# dm64lc_cslr_pci_002 register map
Vendor: Texas Instruments
Peripheral module from a debugger description file.
Registers are 32-bit, access not given, reset 0x0 unless marked. A register's access mark holds for its fields unless they carry their own. Offsets are as the file gives them; lines under a group give offsets from that group; [hi:lo] are bit positions; {n}, {i} and the like mark numbered series; 'fields as' and 'values as' point back to an identical list; <NAME> marks a mode.

## PCICFG — Peripheral Component Interconnect Interface
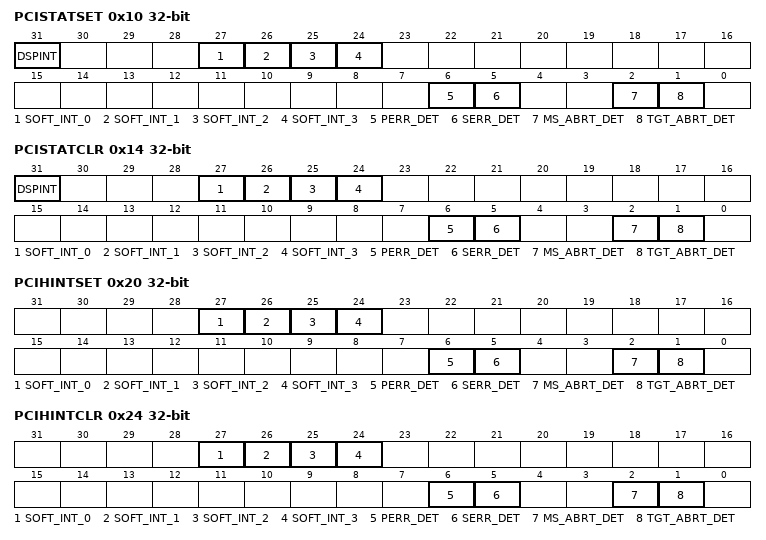
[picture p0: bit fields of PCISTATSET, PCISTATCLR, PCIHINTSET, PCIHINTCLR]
0x10 PCISTATSET — Sets internal Status Register
  [31] DSPINT — DSP interrupt bit. Writing a 1 to this bit forces a host-to-DSP interrupt (DSPINT). The DSPINT bit of the internal Back End Application Interrupt Enable Register must be set to 1 before the interrupt can reach the DSP. 0 A write of 0 is ignored. 1 Host-to-DSP interrupt (DSPINT) is asserted. (access RW1S)
  [27-n] SOFT_INT_{n} (n=0..3) — Software interrupt set bits. Writing a 1 to these bits sets the corresponding software interrupt. If the corresponding bit in the PCI Host Interrupt Enable Register is also set to 1, an interrupt is generated to the host via the PINTA pin. The host-to-DSP interrupt (DSPINT) is also generated if the corresponding bit in the PCI Back End Application Interrupt Enable Register is set to 1. 0 A write of 0 is ignored 1 Generate software interrupt (access RW1S)
  [6] PERR_DET — Parity error detect bit. Writing a 1 to this bit set a parity error. 0 A write of 0 is ignored. 1 Set parity error (access RW1S)
  [5] SERR_DET — System error detect bit. Writing a 1 to this bit set a system error. 0 A write of 0 is ignored. 1 Set system error (access RW1S)
  [2] MS_ABRT_DET — Master abort detect bit. Writing a 1 to this bit set master abort. 0 A write of 0 is ignored. 1 Set master abort (access RW1S)
  [1] TGT_ABRT_DET — Set target abort detect bit.Writing a 1 to this bit set target abort. 0 A write of 0 is ignored. 1 Set target abort (access RW1S)
0x14 PCISTATCLR — Clears internal Status Register
  [31] DSPINT — DSP interrupt bit. Writing a 1 to this bit deasserts the host-to-DSP interrupt (DSPINT). 0 A write of 0 is ignored. 1 Host-to-DSP interrupt (DSPINT) is deasserted. (access RW1C)
  [27-n] SOFT_INT_{n} (n=0..3) — Software interrupt clear bits. Writing a 1 to these bits clears the corresponding software interrupt. 0 A write of 0 is ignored 1 Clear software interrupt (access RW1C)
  [6] PERR_DET — Parity Error Detect bit. Writing 1 to this bit Clear the parity error bit. 0 A write of 0 is ignored. 1 Clear the parity error (access RW1C)
  [5] SERR_DET — Sytem Error Detect bit. Writing 1 to this bit clear system error bit. 0 A write of 0 is ignored. 1 Clear the system error (access RW1C)
  [2] MS_ABRT_DET — Master abort detect bit. Writing 1 to this bit clear master abort error bit. 0 A write of 0 is ignored. 1 Clears master abort (access RW1C)
  [1] TGT_ABRT_DET — Target abort detect bit. Writing 1 to this bit clear target abort error bit. 0 A write of 0 is ignored. 1 Clears target abort (access RW1C)
0x20 PCIHINTSET — Set internal Host Interrupt Enable Register
  [27-n] SOFT_INT_{n} (n=0..3) — Software interrupt enable bits. Writing a 1 to these bits enables the corresponding software interrupt. When the corresponding bit in the internal Status Register is set to 1, an interrupt is generated to the host via the PINTA pin. 0 A write of 0 is ignored 1 Enables software interrupt (access RW1S)
  [6] PERR_DET — Parity error detect enable bit. Writing 1 to this bit allows an interrupt to be generated to the host when a parity error is detected. 0 A write of 0 is ignored. 1 Enables interrupt to host when parity error is detected (access RW1S)
  [5] SERR_DET — System error detect enable bit. Writing 1 to this bit allows an interrupt to be generated to the host when a system error is detected 0 A write of 0 is ignored. 1 Enables interrupt to host when system error is detected (access RW1S)
  [2] MS_ABRT_DET — Master abort detect enable bit. Writing 1 to this bit allows an interrupt to be generated to the host when a master abort is detected. 0 A write of 0 is ignored. 1 Enables interrupt to the host when master abort is detected (access RW1S)
  [1] TGT_ABRT_DET — Target abort detect enable bit. Writing 1 to this bit allows an interrupt to be generated to the host when a target abort is detected 0 A write of 0 is ignored. 1 Enables interrupt to the host when a target abort is detected (access RW1S)
0x24 PCIHINTCLR — Clear internal Host Interrupt Enable Register
  [27-n] SOFT_INT_{n} (n=0..3) — Software interrupt disable bits. Writing a 1 to these bits disables the corresponding software interrupt. 0 A write of 0 is ignored 1 Disables software interrupt (access RW1C)
  [6] PERR_DET — Parity error detect disable bit. Writing 1 to this bit disable the parity error detection 0 A write of 0 is ignored. 1 Disables the parity error detection (access RW1C)
  [5] SERR_DET — System error detect disable bit. Writing 1 to this bit disable the system error detection 0 A write of 0 is ignored. 1 Disables the System error detection (access RW1C)
  [2] MS_ABRT_DET — Master abort detect disable bit. Writing 1 to this bit disable the master abort detection 0 A write of 0 is ignored. 1 Disables the master abort detection (access RW1C)
  [1] TGT_ABRT_DET — Master abort detect disable bit. Writing 1 to this bit disable the master abort detection 0 A write of 0 is ignored. 1 Disables the master abort detection (access RW1C)
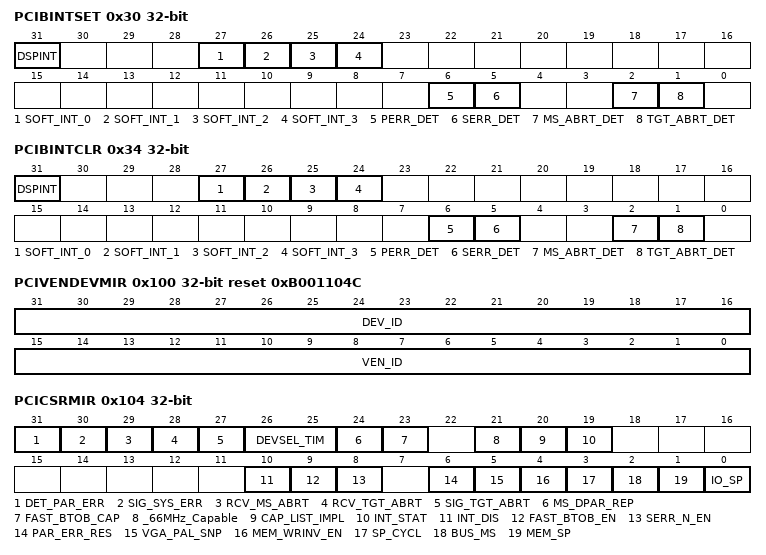
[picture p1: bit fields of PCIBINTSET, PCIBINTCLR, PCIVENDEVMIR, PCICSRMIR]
0x30 PCIBINTSET — Set internal Back End Application Interrupt Enable Register
  [31] DSPINT — DSP interrupt enable bit. Writing a 1 to this bit enables the host-to-DSP interrupt (DSPINT). 0 A write of 0 is ignored. 1 Enables the host-to-DSP interrupt (DSPINT). (access RW1S)
  [27-n] SOFT_INT_{n} (n=0..3) — Software interrupt enable bits. Writing a 1 to these bits enables the corresponding software interrupt. When the corresponding bit in the internal Status Register is set to 1, an interrupt is generated to the DSP via the DSPINT interrupt line. 0 A write of 0 is ignored 1 Enables software interrupt (access RW1S)
  [6] PERR_DET — Parity error detect enable bit. Writing a 1 to this bit enables the Parity error detection 0 A write of 0 is ignored. 1 Enables the parity error detection (access RW1S)
  [5] SERR_DET — System error detect enable bit. Writing a 1 to this bit enables the System error detection 0 A write of 0 is ignored. 1 Enables the system error detection (access RW1S)
  [2] MS_ABRT_DET — Master abort detect enable bit. Writing a 1 to this bit enables the Maste abort detection error 0 A write of 0 is ignored. 1 Enables the master abort detection (access RW1S)
  [1] TGT_ABRT_DET — Target abort detect enable bit. Writing a 1 to this bit enables the Target abort detection error 0 A write of 0 is ignored. 1 Enables the target abort detection (access RW1S)
0x34 PCIBINTCLR — Clear internal Back End Application Interrupt Enable Register
  [31] DSPINT — DSP interrupt disable bit. Writing a 1 to this bit disables the host-to-DSP interrupt (DSPINT). 0 A write of 0 is ignored. 1 Disables the host-to-DSP interrupt (DSPINT). (access RW1C)
  [27-n] SOFT_INT_{n} (n=0..3) — Software interrupt disable bits. Writing a 1 to these bits disables the corresponding software interrupt. 0 A write of 0 is ignored 1 Disables software interrupt (access RW1C)
  [6] PERR_DET — Parity error detect disable bit. Writing a 1 to this bit disable the Parity error detection 0 A write of 0 is ignored. 1 Disables the parity error detection (access RW1C)
  [5] SERR_DET — System error detect disable bit. Writing a 1 to this bit disable the System error detection 0 A write of 0 is ignored. 1 Disables the system error detection (access RW1C)
  [2] MS_ABRT_DET — Master abort detect disable bit. Writing a 1 to this bit disable the Master abort detection 0 A write of 0 is ignored. 1 Disables the master abort detection (access RW1C)
  [1] TGT_ABRT_DET — Target abort detect disable bit.Writing a 1 to this bit disable the Target abort detection 0 A write of 0 is ignored. 1 Disables the target abort detection (access RW1C)
0x100 PCIVENDEVMIR rw reset 0xB001104C — This register is used to initialize the Vendor ID and / or Device ID in the PCI Configuration Space
  [31:16] DEV_ID — Device ID. Identifies a specific device from the manufacturer. The Device ID is specified by the device manufacturer
  [15:0] VEN_ID — Vendor ID.Uniquely identifies the manufacturer of the device. The Vendor ID is specified by the PCI Special Interest Group to insure uniqueness
0x104 PCICSRMIR (reset mask 0xF9FFFFFF) — This register is used to initialize certain bits in the PCI Configuration Space Command / Status register
  [31] DET_PAR_ERR — Detected Parity Error bit. This bit is set by the PCI to indicate that it detected a parity error (access RW1C)
  [30] SIG_SYS_ERR — Signaled System Error bit.This bit is set by the PCI to indicate that it signaled a system error on the PSERR pin. (access RW1C)
  [29] RCV_MS_ABRT — Received Master Abort bit.This bit is set by the PCI master unit in the PCI to indicate that it terminated a transaction with a master abort (access RW1C)
  [28] RCV_TGT_ABRT — Received Target Abort bit.This bit is set by the PCI master unit in the PCI to indicate that it has received a target abort when acting as a bus master (access RW1C)
  [27] SIG_TGT_ABRT ro — Signaled Target Abort bit.This bit is always 0 since the PCI cannot issue a target abort
  [26:25] DEVSEL_TIM ro — DEVSEL timing bit.This bit indicates the decode response time capability of the device. This bit is hardwired to "01"
  [24] MS_DPAR_REP — Master Data Parity Reported bit This bit is set by the PCI master unit in the PCI when all of the following conditions are met. 1. The PCI asserted PPERR or observed PPERR asserted 2. The PCI master unit was the bus master during the observed PPERR assertion 3. The PAR_ERR_RES bit ( Bit 6) is Set. (access RW1C)
  [23] FAST_BTOB_CAP ro — Fast Back to Back Capable bit.This bit indicates that the device is capable of performing fast back to back transactions. This bit is hardwired to "0"
  [21] _66MHz_Capable rw — 66MHz Capable bit. This bit defaults to 0 since the PCI on DM643x devices only supports 33MHz operation.
  [20] CAP_LIST_IMPL rw — Capabilities List Implemented bit. This bit defaults to 0 since the PCI on DM643x devices does not implement a capabilities list
  [19] INT_STAT ro — Interrupt Status bit.This bit indicates the current interrupt status for the function as generated by the interrupt registers in the back end interface. If this bit is set and INT_DIS(bit 10) bit is cleared, the PINTA pin will be asserted low. The bit INT_DIS has no effect on the value of this bit.
  [10] INT_DIS rw — Interrupt Disable bit.This bit is a disable for the output driver on the PINTA pin. If this bit is set, the interrupt condition will not appear on the external PINTA pin
  [9] FAST_BTOB_EN ro — Fast Back to Back Enable bit.This bit controls whether or not the device is allowed to perform back to back writes to different targets. This bit is hardwired to a "0".
  [8] SERR_N_EN rw — System error enable bit is an enable for the output driver on the PSERR pin
  [6] PAR_ERR_RES rw — Parity Error response bit. This bit controls whether or not the device responds to detected parity errors. If this bit is set, the PCI will respond normally to parity errors. If this bit is cleared, the PCI will set its DET_PAR_ERR bit (Bit 31) when an error is detected, but does not assert PPERR and continues normal operation.
  [5] VGA_PAL_SNP ro — VGA Palette Snoop. This bit hardwired to a "0".
  [4] MEM_WRINV_EN rw — Memory Write and Invalidate Enable bit.This bit enables the device to use the Memory Write and Invalidate command.If this bit is cleared, the PCI will not attempt to use the Memory Write and Invalidate command.
  [3] SP_CYCL ro — Special Cycles bit controls the device's response to special cycle commands. If this bit is cleared, the device will ignore all special cycle commands. If this bit is set to 1, the device can monitor special cycle commands.
  [2] BUS_MS rw — Bus Master bit enables the device to act as a PCI bus master.If this bit is cleared, the device will not act as a master on the PCI bus.
  [1] MEM_SP rw — Memory Space bit enables the device to respond to memory accesses within it's address space.If this bit is cleared, the PCI will not respond to memory mapped accesses.
  [0] IO_SP ro — I/O Space bit enables the device to respond to I/O accesses within it's address space. If this bit is cleared, the PCI will not respond to IO mapped accesses.The PCI does not support IO accesses as a slave therefore this bit is hardwired to 0.
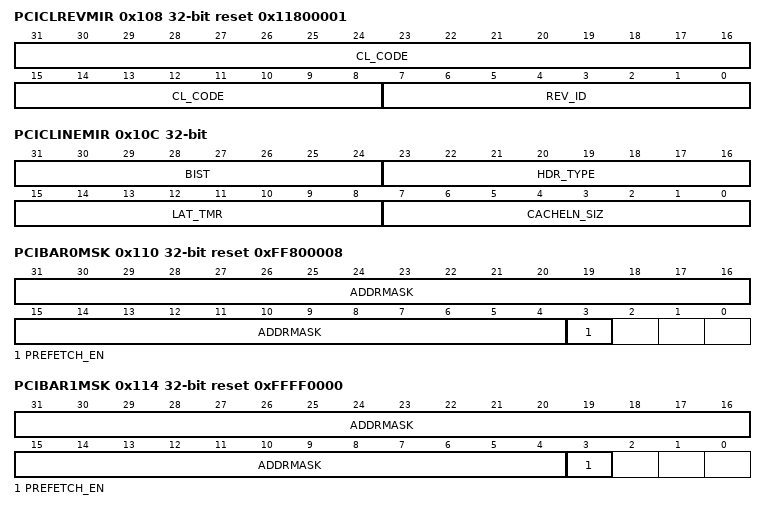
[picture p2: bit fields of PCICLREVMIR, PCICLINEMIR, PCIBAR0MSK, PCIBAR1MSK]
0x108 PCICLREVMIR rw reset 0x11800001 — This register is used to initialize the Class Code and / or Revision ID
  [31:8] CL_CODE — Class Code identifies the generic and specific function and programming interface of the device. The Class Code is specified by the device manufacturer
  [7:0] REV_ID — Revision ID identifies a revision of the specific device. The Revision ID is specified by the device manufacturer
0x10C PCICLINEMIR access per field — This register is used to set latency timer and cacheline size
  [31:24] BIST ro — Built-in Self Test bit. Hardwired to 0
  [23:16] HDR_TYPE ro — Header Type identifies the layout of bytes 10h through 3Fh and if the device is single or multi-function
  [15:8] LAT_TMR rw — Latency Timer is provided so that the host can restrict the continued usage of the PCI bus by a master involved in a multiple data cycle transaction.
  [7:0] CACHELN_SIZ rw — Cacheline Size is provided so that the host can inform the device of the cache line size in units of 32 bit words.The value of this register is used by the PCI as a master device to determine whether to use Memory Write, Memory Write and Invalidate, Read, Read Line, or Read Multiple commands for accessing memory. This register is also used by the slave state machine to determine the size of prefetches that are performed on the Slave Back End Interface. Supported values for this register are as follows: 0b00000000 - Disabled 0b00000100 -Cache Line is 16 bytes 0b00001000 - Cache Line is 32 bytes 0b00010000 - Cache Line is 64 bytes 0b00100000 - Cache Line is 128 bytes Writing an unsupported value to this register will result in the value being set to 0
0x110 PCIBAR0MSK reset 0xFF800008 — The Base Address Mask Registers control the size and prefetchability of the PCI Configuration Base Address Registers
  [31:4] ADDRMASK rw — Address Mask Bit.These bits control the writability of corresponding bits in the corresponding PCI Configuration Base Address Register.
  [3] PREFETCH_EN rw — Prefetchable enable. This bit specifies whether or not the memory space controlled by the corresponding PCI Configruation Base Address Register is prefetchable.This bit is reflected in bit 3 of the corresponding PCI Configuration Base Address Register
0x114 PCIBAR1MSK reset 0xFFFF0000 — The Base Address Mask Registers control the size and prefetchability of the PCI Configuration Base Address Registers
  [31:4] ADDRMASK rw — Address Mask Bit.These bits control the writability of corresponding bits in the corresponding PCI Configuration Base Address Register.
  [3] PREFETCH_EN rw — Prefetchable enable. This bit specifies whether or not the memory space controlled by the corresponding PCI Configruation Base Address Register is prefetchable. This bit is reflected in bit 3 of the corresponding PCI Configuration Base Address Register
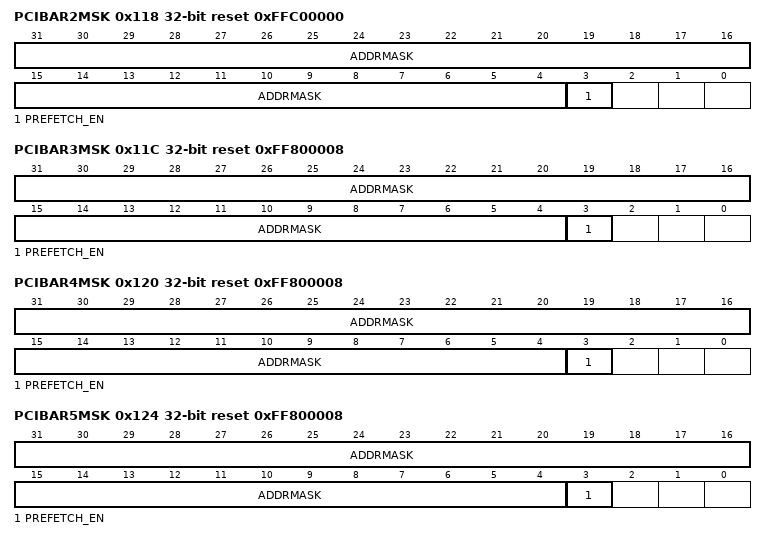
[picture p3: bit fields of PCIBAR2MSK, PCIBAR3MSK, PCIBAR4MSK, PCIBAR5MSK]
0x118 PCIBAR2MSK reset 0xFFC00000 — The Base Address Mask Registers control the size and prefetchability of the PCI Configuration Base Address Registers
  fields as PCIBAR1MSK
0x11C PCIBAR3MSK reset 0xFF800008 — The Base Address Mask Registers control the size and prefetchability of the PCI Configuration Base Address Registers
  fields as PCIBAR0MSK
0x120 PCIBAR4MSK reset 0xFF800008 — The Base Address Mask Registers control the size and prefetchability of the PCI Configuration Base Address Registers
  fields as PCIBAR1MSK
0x124 PCIBAR5MSK reset 0xFF800008 — The Base Address Mask Registers control the size and prefetchability of the PCI Configuration Base Address Registers
  fields as PCIBAR1MSK
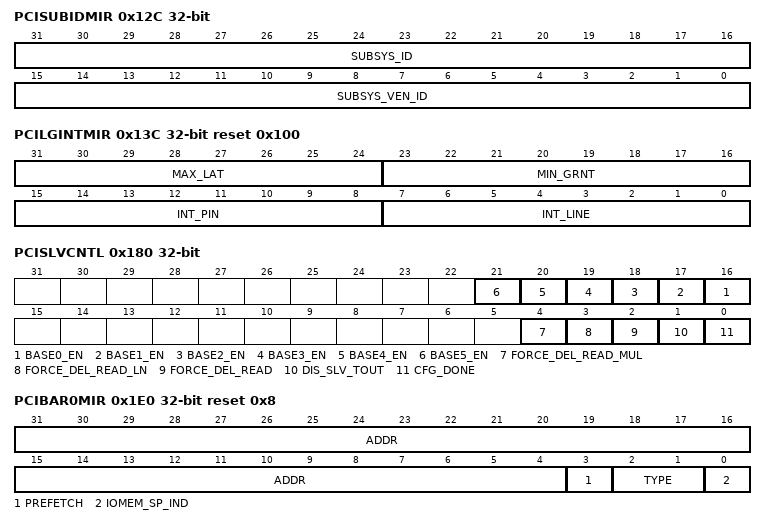
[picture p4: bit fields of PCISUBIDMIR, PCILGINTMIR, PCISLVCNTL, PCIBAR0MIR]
0x12C PCISUBIDMIR rw — PCI Subsystem Vendor ID / Subsystem ID
  [31:16] SUBSYS_ID — Subsystem Id. Identifies the board level device.The Subsystem ID is specified by the board level manufacturer.
  [15:0] SUBSYS_VEN_ID — Subsystem Vendor Id. Identifies the board level manufacturer. The Subsystem Vendor ID is specified by the PCI Special Interest Group.
0x134 PCICPBPTRMIR reset 0x40 — Capabilities Pointer
  [7:0] CAP ro — Capabilities Pointer. This constant specifies the address in configuration space where the first entry in the capabilities list is located.
0x13C PCILGINTMIR access per field reset 0x100 — Set Max Latency / Min Grant
  [31:24] MAX_LAT rw — Maximum Latency bit specifies how often the device needs to gain access to the PCI bus in 0.25 micro sec units.
  [23:16] MIN_GRNT rw — Minimum Grant bit specifies the length of the burst period for the device needs in 0.25 micro sec units.
  [15:8] INT_PIN ro — Interrupt Pin bit tells which interrupt pin the device uses. This register is hardwired to a 01h in the PCI to indicate that interrupt A will be used.
  [7:0] INT_LINE rw — Interrupt Line pin bit. The value in this 8 bit register is written by the host and indicates which input of the system interrupt controller the PCI interrupt pin is connected to.
0x180 PCISLVCNTL (reset mask 0xFFC0FFFF) — PCI Slave Control
  [n+16] BASE{n}_EN rw (n=0..5) — Enable/Disable BASE {n} Configuration 0 - Disable BASE {n} Configuration 1 - Enable BASE {n} Configuration
  [4] FORCE_DEL_READ_MUL rw — Force Delayed Read Multiple bit. 0 - Slave should respond with normal 16 clock cycle timeout and retry mechanism for Memory Read Multiple transactions 1 - Slave should immediately respond with a retry whenever a Memory Read Multiple transaction is decoded for this slave.
  [3] FORCE_DEL_READ_LN rw — Force Delayed Read Line bit. 0 - Slave should respond with normal 16 clock cycle timeout and retry mechanism for Memory Read Line transactions 1 - Slave should immediately respond with a retry whenever a Memory Read Line transaction is decoded for this slave.
  [2] FORCE_DEL_READ rw — Force Delayed Read bit. 0 - Slave should respond with normal 16 clock cycle timeout and retry mechanism for Memory Read transactions 1 - Slave should immediately respond with a retry whenever a Memory Read transaction is decoded for this slave.
  [1] DIS_SLV_TOUT rw — Disable Slave timeout bit. 0 - Slave responds with normal 16 clock cycle timeout mechanism 1 - Slave will insert wait states on the PCI Bus indefinitely until the access is ready to complete
  [0] CFG_DONE rw — Configuration Done bit indicates if the Configuration Registers have been loaded with their proper reset values: 0 - Configuration Registers are being loaded. No access allowed into PCI interface. 1 - Configuration Registers loading is complete. PCI interface will accept accesses.
0x1C0 PCIBAR0TRL reset 0x10800000 — This register control the translation of transaction addresses
  [31:4] TRANS_ADDR rw — Translation Address bit. This is the address that is to bitwise replace the slave transaction address.This is multiplexed on a bitwise basis with the original PCI address using the corresponding PCI Base Address Mask register bits 31:4 as the multiplexer select.
0x1C4 PCIBAR1TRL reset 0x20000000 — This register control the translation of transaction addresses
  fields as PCIBAR0TRL
0x1C8 PCIBAR2TRL reset 0x1C00000 — This register control the translation of transaction addresses
  fields as PCIBAR0TRL
0x1CC PCIBAR3TRL reset 0x10800000 — This register control the translation of transaction addresses
  fields as PCIBAR0TRL
0x1D0 PCIBAR4TRL reset 0x10800000 — This register control the translation of transaction addresses
  fields as PCIBAR0TRL
0x1D4 PCIBAR5TRL reset 0x80000000 — This register control the translation of transaction addresses
  fields as PCIBAR0TRL
0x1E0 PCIBAR0MIR reset 0x8 — PCI Base Address 0 Mirror Register
  [31:4] ADDR — Address bit. These bits can be written by the host in order to allow initialization of the base address at startup (access RW DEPENDING ON MASK)
  [3] PREFETCH ro — Prefetchable bit.This bit specifies whether or not the memory space controlled by this base address register is prefetchable
  [2:1] TYPE ro — These bits indicate the size of the base address register
  [0] IOMEM_SP_IND ro — IO/ Memory Space Indicator bit.This bit indicates whether the base address maps into the host's memory or I/O space. This bit is hardwired to a 0
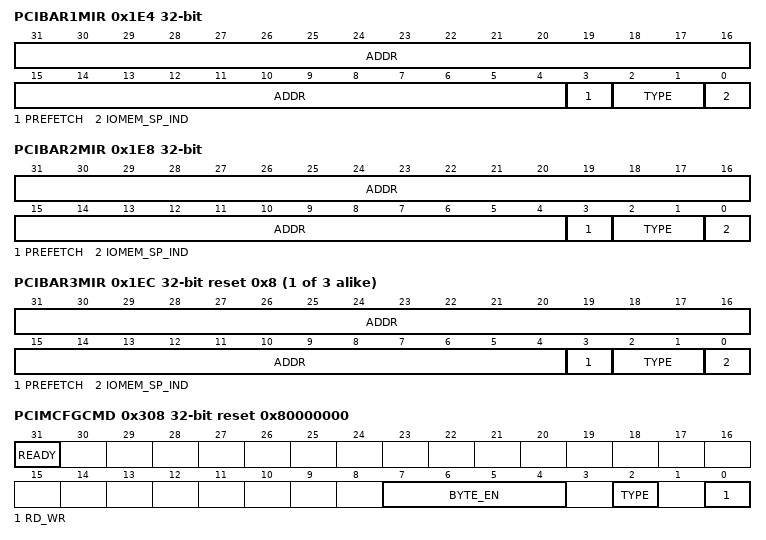
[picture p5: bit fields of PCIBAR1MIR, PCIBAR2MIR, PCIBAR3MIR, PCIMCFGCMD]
0x1E4 PCIBAR1MIR — PCI Base Address 1 Mirror Register
  fields as PCIBAR0MIR
0x1E8 PCIBAR2MIR — PCI Base Address 2 Mirror Register
  fields as PCIBAR0MIR
{0x1E0+4i} PCIBAR{i}MIR reset 0x8 (i=3..5) — PCI Base Address {i} Mirror Register
  fields as PCIBAR0MIR
0x300 PCIMCFGDAT rw — PCI Master Configuration / IO Access Data Register
  [31:0] DATA — Software writes the data into this register bit for a configuration/IO write, or reads the data from this register for a configuration/IO read.
0x304 PCIMCFGADR rw — PCI Master Configuration / IO Access Address Register
  [31:0] ADDR — Address for Configuration/IO Transaction. Bits 1:0 are ignored for a Configuration Transaction. Software must ensure that Bits 1:0 of the Address correspond to the BYTE_EN that are written in the Configuration / IO Access Command register for IO transactions to ensure that the access is legal on the PCI bus.
0x308 PCIMCFGCMD reset 0x80000000 — PCI Master Configuration / IO Access Command Register
  [31] READY ro — Ready bit.This bit should be checked to assure that previous transaction is completed. 0 Register is not ready to accept a new command 1 Register is ready to accept a new command
  [7:4] BYTE_EN rw — Byte Enables. This bit used to determine which bytes within the addressed DWORD are being accessed. Byte enables indicate the size of the transfer and must be consistent with the Bits 1:0 of the Address which is specified using the PCI Master Configuration/IO Access Address Register.
  [2] TYPE rw — Type bit. Select Configuration or IO Transaction. 0 - Configuration Transaction 1 - IO Transaction
    0=CONFIG_SPACE (Enable Configuration space access); 1=IO_SPACE (Enable IO space access)
  [0] RD_WR rw — Read/write bit.Select read or write operation 0 - Write 1 - Read
    0=WRITE (Enable Configration/IO Write); 1=READ (Enable Configration/IO Read)
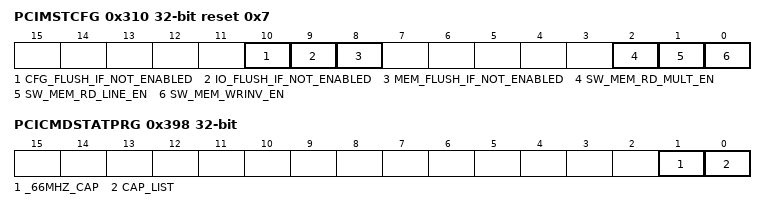
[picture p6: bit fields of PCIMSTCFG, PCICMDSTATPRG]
0x310 PCIMSTCFG reset 0x7 — PCI Master Configuration Register
  [10] CFG_FLUSH_IF_NOT_ENABLED rw — Configuration flush bit. This bit controls whether or not the Master will flush Configuration transactions from the proxyregisters if the Master is not enabled
  [9] IO_FLUSH_IF_NOT_ENABLED rw — IO flush bit. This bit controls whether or not the Master will flush I/O transactions from the proxy registers if the Master is not enabled
  [8] MEM_FLUSH_IF_NOT_ENABLED rw — Memory flush bit. This bit controls whether or not the Master will flush transactions on the pcim interface if the Master is not enabled
  [2] SW_MEM_RD_MULT_EN rw — Memory read multiple enable bit. This bit controls whether or not the Master command generation logic is permitted to use the Memory Read Multiple command
  [1] SW_MEM_RD_LINE_EN rw — Memory read line enable bit. This bit controls whether or not the Master command generation logic is permitted to use the Memory Read Line command
  [0] SW_MEM_WRINV_EN rw — Memory write invalid enable bit. This bit controls whether or not the Master command generation logic is permitted to use the Memory Write and Invalidate command
{0x314+4i} PCIADDSUB_{i} (i=0..31) — The DSP-to-PCI Address Translation registers are used for address translation from DSP to PCI domain
  [31:23] ADD_SUBS rw — Substitutes the 9 MSBs of DSP address
0x394 PCIVENDEVPRG rw reset 0xB001104C — PCI Vendor ID and Device ID Program Register
  [31:0] VENDOR_DEVICE_ID_PROG — This bit provides the default values for VEN_ID and DEV_ID
0x398 PCICMDSTATPRG — Provides default values for the command status mirror register
  [1] _66MHZ_CAP rw — This bit provides default value for 66MHZ_CAP(Bit 21) bit of command status register of PCI
  [0] CAP_LIST rw — This bit provides default value for CAP_LIST_IMPL(Bit 20) bit of command status register of PCI
0x39C PCICLREVPRG rw reset 0x11800001 — Provides default values to Class code/Revision ID mirror register
  [31:0] CLASS_CODE_REV_ID_PROG — This bit provides default values to CL_ CODE and REV_ID
0x3A0 PCISUBIDPRG rw — Provides default values to subsystem vendor id and subsystem id
  [31:0] SUBSYS_VENDOR_ID_SUBSYS_ID_PROG — This bit provides default value to SUBSYS_VEN_ID and SUBSYS_ID
0x3A4 PCIMAXLGPRG — Provides default values for max latency and min grant
  [15:0] MAX_LAT_MIN_GRANT_PROG rw — This bit Provides default values for MAX_LAT,MIN_GRNT
0x3AC PCICFGDONE — Supplies configuration done to PCI core
  [0] CONFIG_DONE rw — Configuration done bit. Holds off accesses to the PCI until configuration by the DSP ROM code is complete. 1 Configuration complete, accesses to the PCI are allowed. 0 Configuration in progress, accesses to the PCI are not permitted.
0x3B0 PCIBAR0MPRG reset 0xFF80000 — Default value for PCI base address mask register 0
  [27:0] MASK rw — This bit provides default value for Base address mask register0
0x3B4 PCIBAR1MPRG reset 0xFFFF000 — Default value for PCI base address mask register 1
  [27:0] MASK rw — This bit provides default value for Base address mask register1
0x3B8 PCIBAR2MPRG reset 0xFFC0000 — Default value for PCI base address mask register 2
  [27:0] MASK rw — This bit provides default value for Base address mask register2
{0x3B0+4i} PCIBAR{i}MPRG reset 0xFF80000 (i=3..5) — Default value for PCI base address mask register {i}
  [27:0] MASK rw — This bit provides default value for Base address mask register{i}
0x3C8 PCIBAR0PRG reset 0x1 — Default value for PCI base address register 0
  [0] PREFETCH rw — This bit provides default value for prefetchable bit of Base address 0 Register
0x3CC PCIBAR1PRG — Default value for PCI base address register 1
  [0] PREFETCH rw — This bit provides default value for prefetchable bit of Base address 1 Register
0x3D0 PCIBAR2PRG — Default value for PCI base address register 2
  [0] PREFETCH rw — This bit provides default value for prefetchable bit of Base address 2 Register
{0x3C8+4i} PCIBAR{i}PRG reset 0x1 (i=3..5) — Default value for PCI base address register {i}
  [0] PREFETCH rw — This bit provides default value for prefetchable bit of Base address {i} Register
0x3E0 PCIBAR0TRLPRG reset 0x1080000 — Default value for Base address translation register 0
  [27:0] TRANS_ADDR rw — Base address translation register 0 program bit. This bit provides default value for Base address translation register 0
0x3E4 PCIBAR1TRLPRG reset 0x2000000 — Default value for Base address translation register 1
  [27:0] TRANS_ADDR rw — Base address translation register 1 program bit. This bit provides default value for Base address translation register 1
0x3E8 PCIBAR2TRLPRG reset 0x1C0000 — Default value for Base address translation register 2
  [27:0] TRANS_ADDR rw — Base address translation register 2 program bit. This bit provides default value for Base address translation register 2
0x3EC PCIBAR3TRLPRG reset 0x1080000 — Default value for Base address translation register 3
  [27:0] TRANS_ADDR rw — Base address translation register 3 program bit. This bit provides default value for Base address translation register 3
0x3F0 PCIBAR4TRLPRG reset 0x1080000 — Default value for Base address translation register 4
  [27:0] TRANS_ADDR rw — Base address translation register 4 program bit. This bit provides default value for Base address translation register 4
0x3F4 PCIBAR5TRLPRG (reset mask 0xF0000000) — Default value for Base address translation register 5
  [27:0] TRANS_ADDR rw — Base address translation register 5 program bit. This bit provides default value for Base address translation register 5
0x3F8 PCIBASENPRG reset 0x3F — Default value for enables for the base address
  [5:0] BASE_EN rw — Base Enable Program bit. These bits controls the 21:16 Bits of the PCI Slave control register. These bits provides default value for base address enable for base address0 (bit 0), base address1 (bit1), base address2 (bit2), base address3 (bit3), base address4 (bit4),base address5 (bit5)
